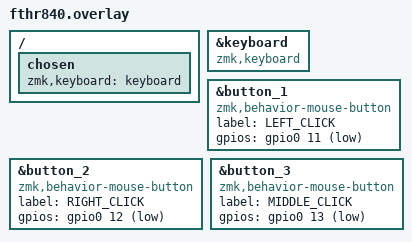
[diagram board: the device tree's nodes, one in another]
/ {
    chosen {
        zmk,keyboard = <&keyboard>;  // Required, even for mouse-only
    };
};

&keyboard {
    compatible = "zmk,keyboard";
};

// Define GPIOs for your buttons
&button_1 {
    label = "LEFT_CLICK";
    compatible = "zmk,behavior-mouse-button";
    gpios = <&gpio0 11 GPIO_ACTIVE_LOW>;
};

&button_2 {
    label = "RIGHT_CLICK";
    compatible = "zmk,behavior-mouse-button";
    gpios = <&gpio0 12 GPIO_ACTIVE_LOW>;
};

&button_3 {
    label = "MIDDLE_CLICK";
    compatible = "zmk,behavior-mouse-button";
    gpios = <&gpio0 13 GPIO_ACTIVE_LOW>;
};
